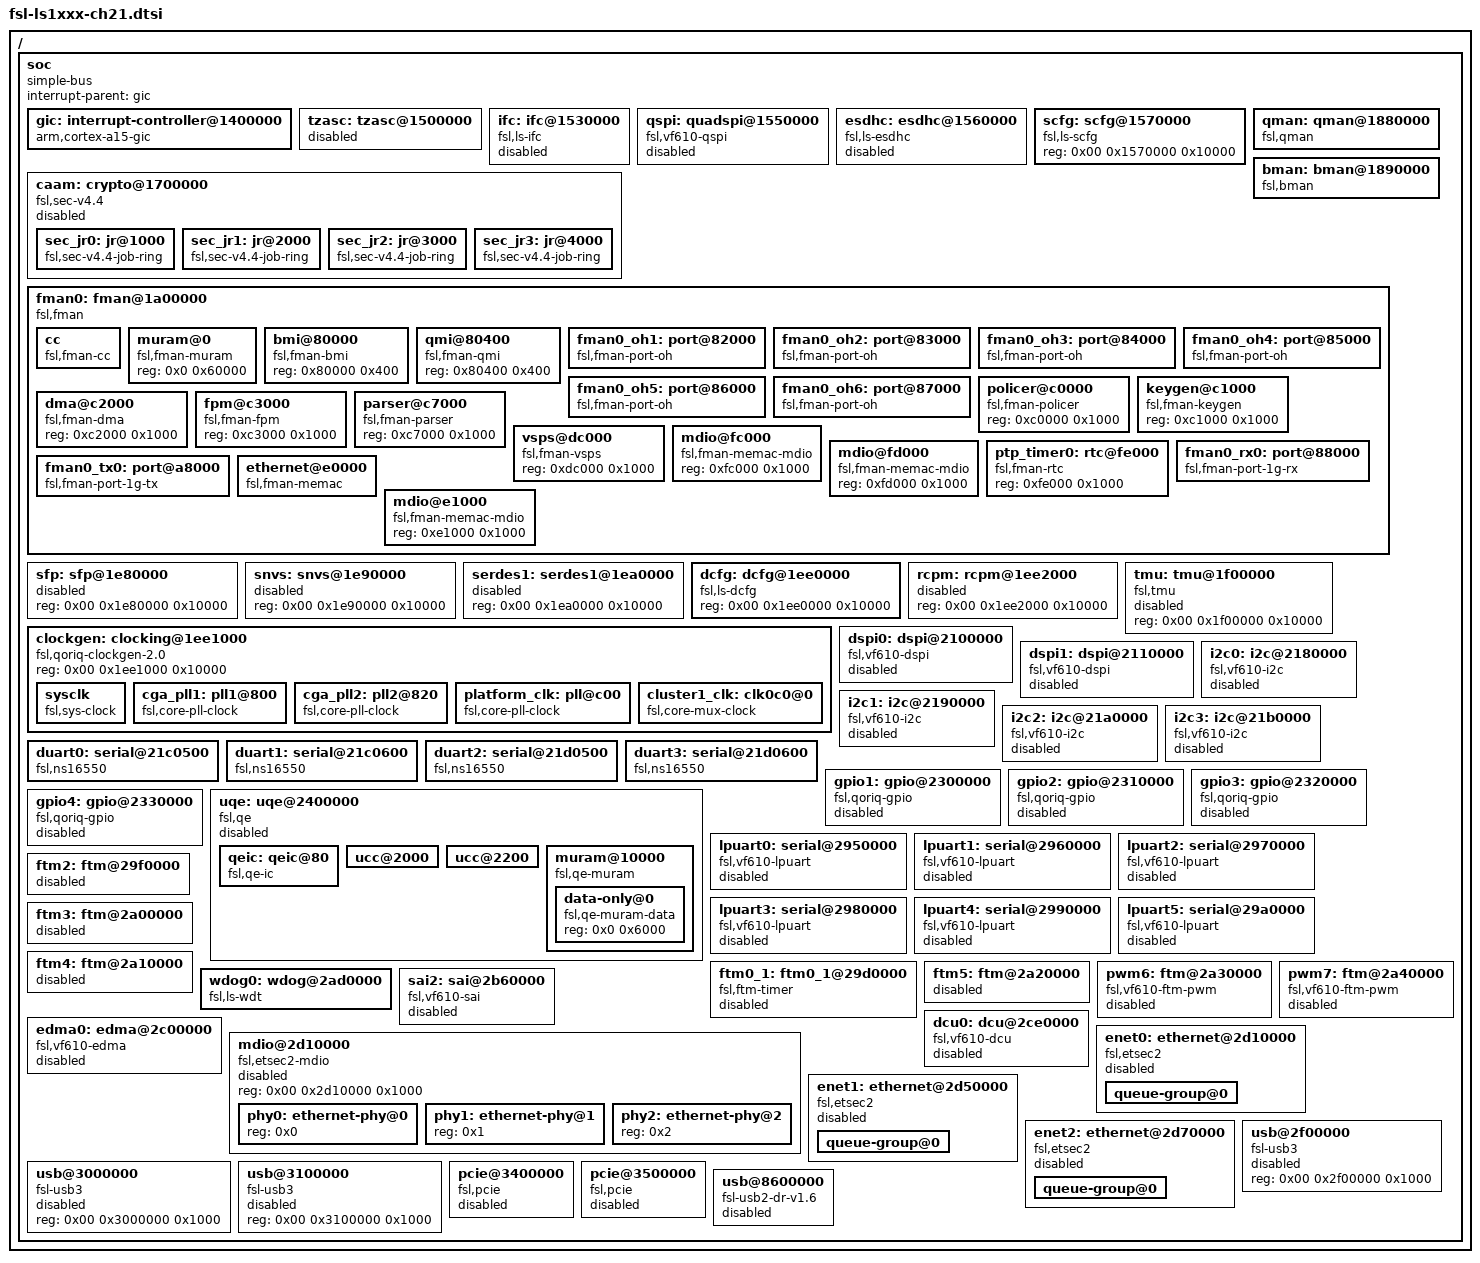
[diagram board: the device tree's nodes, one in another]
/*
 * Device Tree Include file for Freescale Layerscape 1xxx family SoC
 * (compliant to Chassis 2.1 specifications).
 *
 * Copyright 2014, Freescale Semiconductor Inc.
 * Li Yang <leoli@freescale.com>
 *
 * Redistribution and use in source and binary forms, with or without
 * modification, are permitted provided that the following conditions are met:
 *     * Redistributions of source code must retain the above copyright
 *       notice, this list of conditions and the following disclaimer.
 *     * Redistributions in binary form must reproduce the above copyright
 *       notice, this list of conditions and the following disclaimer in the
 *       documentation and/or other materials provided with the distribution.
 *     * Neither the name of Freescale Semiconductor nor the
 *       names of its contributors may be used to endorse or promote products
 *       derived from this software without specific prior written permission.
 *
 *
 * ALTERNATIVELY, this software may be distributed under the terms of the
 * GNU General Public License ("GPL") as published by the Free Software
 * Foundation, either version 2 of that License or (at your option) any
 * later version.
 *
 * THIS SOFTWARE IS PROVIDED BY Freescale Semiconductor ``AS IS'' AND ANY
 * EXPRESS OR IMPLIED WARRANTIES, INCLUDING, BUT NOT LIMITED TO, THE IMPLIED
 * WARRANTIES OF MERCHANTABILITY AND FITNESS FOR A PARTICULAR PURPOSE ARE
 * DISCLAIMED. IN NO EVENT SHALL Freescale Semiconductor BE LIABLE FOR ANY
 * DIRECT, INDIRECT, INCIDENTAL, SPECIAL, EXEMPLARY, OR CONSEQUENTIAL DAMAGES
 * (INCLUDING, BUT NOT LIMITED TO, PROCUREMENT OF SUBSTITUTE GOODS OR SERVICES;
 * LOSS OF USE, DATA, OR PROFITS; OR BUSINESS INTERRUPTION) HOWEVER CAUSED AND
 * ON ANY THEORY OF LIABILITY, WHETHER IN CONTRACT, STRICT LIABILITY, OR TORT
 * (INCLUDING NEGLIGENCE OR OTHERWISE) ARISING IN ANY WAY OUT OF THE USE OF THIS
 * SOFTWARE, EVEN IF ADVISED OF THE POSSIBILITY OF SUCH DAMAGE.
 */

/ {

	soc {
		#address-cells = <2>;
		#size-cells = <1>;
		compatible = "simple-bus";
		interrupt-parent = <&gic>;

		gic: interrupt-controller@1400000 {
			compatible = "arm,cortex-a15-gic";
			#interrupt-cells = <3>;
			interrupt-controller;
			reg = <0x00 0x1401000 0x1000>,
				<0x00 0x1402000 0x1000>,
				<0x00 0x1404000 0x2000>,
				<0x00 0x1406000 0x2000>;
		};

		tzasc: tzasc@1500000 {
			reg = <0x00 0x1500000 0x10000>;
			interrupts = <0 93 0x04>;
			status = "disabled";
		};

		ifc: ifc@1530000 {
			compatible = "fsl,ls-ifc", "fsl,ifc", "simple-bus";
			reg = <0x00 0x1530000 0x10000>;
			interrupts = <0 43 0x04>;
			status = "disabled";
		};

		qspi: quadspi@1550000 {
			#address-cells = <1>;
			#size-cells = <0>;
			compatible = "fsl,vf610-qspi";
			reg = <0x00 0x1550000 0x10000>;
			interrupts = <0 99 0x04>;
			clock-names = "qspi_en", "qspi";
			status = "disabled";
		};

		esdhc: esdhc@1560000 {
			compatible = "fsl,ls-esdhc", "fsl,esdhc";
			reg = <0x00 0x1560000 0x10000>;
			interrupts = <0 62 0x04>;
			clock-frequency = <0>;
			voltage-ranges = <1800 3300>;
			bus-width = <4>;
			status = "disabled";
		};

		scfg: scfg@1570000 {
			compatible = "fsl,ls-scfg";
			reg = <0x00 0x1570000 0x10000>;
		};

		caam: crypto@1700000 {
			compatible = "fsl,sec-v4.4", "fsl,sec-v4.0";
			fsl,sec-era = <3>;
			#address-cells = <1>;
			#size-cells = <1>;
			ranges = <0x0 0x00 0x1700000 0x10000>;
			reg = <0x00 0x1700000 0x10000>;
			interrupts	 = <0 75 0x04>;
			status = "disabled";

			sec_jr0: jr@1000 {
				compatible = "fsl,sec-v4.4-job-ring", "fsl,sec-v4.0-job-ring";
				reg	   = <0x1000 0x1000>;
				interrupts = <0 71 0x04>;
			};

			sec_jr1: jr@2000 {
				compatible = "fsl,sec-v4.4-job-ring", "fsl,sec-v4.0-job-ring";
				reg	   = <0x2000 0x1000>;
				interrupts = <0 72 0x04>;
			};

			sec_jr2: jr@3000 {
				compatible = "fsl,sec-v4.4-job-ring", "fsl,sec-v4.0-job-ring";
				reg	   = <0x3000 0x1000>;
				interrupts = <0 73 0x04>;
			};

			sec_jr3: jr@4000 {
				compatible = "fsl,sec-v4.4-job-ring", "fsl,sec-v4.0-job-ring";
				reg	   = <0x4000 0x1000>;
				interrupts = <0 74 0x04>;
			};
		};

		qman: qman@1880000 {
			compatible = "fsl,qman";
			reg = <0x00 0x1880000 0x10000>;
			interrupts = <0 77 0x4>;
		};

		bman: bman@1890000 {
			compatible = "fsl,bman";
			reg = <0x00 0x1890000 0x10000>;
			interrupts = <0 77 0x4>;
		};

		fman0: fman@1a00000 {
			#address-cells = <1>;
			#size-cells = <1>;
			cell-index = <0>;
			compatible = "fsl,fman", "simple-bus";
			ranges = <0x0 0x00 0x1a00000 0x100000>;
			reg = <0x00 0x1a00000 0x100000>;
			clock-frequency = <0>;
			interrupts =	<0 44 0x04>,	/* fman 76 (-32)*/
					<0 45 0x04>;	/* fman-error 77 (-32)*/

			cc {
				compatible = "fsl,fman-cc";
			};

			muram@0 {
				compatible = "fsl,fman-muram";
				reg = <0x0 0x60000>;
			};

			bmi@80000 {
				compatible = "fsl,fman-bmi";
				reg = <0x80000 0x400>;
			};

			qmi@80400 {
				compatible = "fsl,fman-qmi";
				reg = <0x80400 0x400>;
			};

			fman0_oh1: port@82000 {
				cell-index = <0>;
				compatible = "fsl,fman-port-oh";
				reg = <0x82000 0x1000>;
				fsl,qman-channel-id = <0x802>;
			};

			fman0_oh2: port@83000 {
				cell-index = <1>;
				compatible = "fsl,fman-port-oh";
				reg = <0x83000 0x1000>;
				fsl,qman-channel-id = <0x803>;
			};

			fman0_oh3: port@84000 {
				cell-index = <2>;
				compatible = "fsl,fman-port-oh";
				reg = <0x84000 0x1000>;
				fsl,qman-channel-id = <0x804>;
			};

			fman0_oh4: port@85000 {
				cell-index = <3>;
				compatible = "fsl,fman-port-oh";
				reg = <0x85000 0x1000>;
				fsl,qman-channel-id = <0x805>;
			};

			fman0_oh5: port@86000 {
				cell-index = <4>;
				compatible = "fsl,fman-port-oh";
				reg = <0x86000 0x1000>;
				fsl,qman-channel-id = <0x806>;
			};

			fman0_oh6: port@87000 {
				cell-index = <5>;
				compatible = "fsl,fman-port-oh";
				reg = <0x87000 0x1000>;
				fsl,qman-channel-id = <0x807>;
			};

			policer@c0000 {
				compatible = "fsl,fman-policer";
				reg = <0xc0000 0x1000>;
			};

			keygen@c1000 {
				compatible = "fsl,fman-keygen";
				reg = <0xc1000 0x1000>;
			};

			dma@c2000 {
				compatible = "fsl,fman-dma";
				reg = <0xc2000 0x1000>;
			};

			fpm@c3000 {
				compatible = "fsl,fman-fpm";
				reg = <0xc3000 0x1000>;
			};

			parser@c7000 {
				compatible = "fsl,fman-parser";
				reg = <0xc7000 0x1000>;
			};

			vsps@dc000 {
				compatible = "fsl,fman-vsps";
				reg = <0xdc000 0x1000>;
			};

			mdio@fc000 {
				#address-cells = <1>;
				#size-cells = <0>;
				compatible = "fsl,fman-memac-mdio";
				reg = <0xfc000 0x1000>;
			};

			mdio@fd000 {
				#address-cells = <1>;
				#size-cells = <0>;
				compatible = "fsl,fman-memac-mdio";
				reg = <0xfd000 0x1000>;
			};

			ptp_timer0: rtc@fe000 {
				compatible = "fsl,fman-rtc";
				reg = <0xfe000 0x1000>;
			};

			fman0_rx0: port@88000 {
				cell-index = <0>;
				compatible = "fsl,fman-port-1g-rx";
				reg = <0x88000 0x1000>;
			};

			fman0_tx0: port@a8000 {
				cell-index = <0>;
				compatible = "fsl,fman-port-1g-tx";
				reg = <0xa8000 0x1000>;
				fsl,qman-channel-id = <0x802>;
			};

			ethernet@e0000 {
				cell-index = <0>;
				compatible = "fsl,fman-memac";
				reg = <0xe0000 0x1000>;
				fsl,port-handles = <&fman0_rx0 &fman0_tx0>;
				ptimer-handle = <&ptp_timer0>;
			};

			mdio@e1000 {
				#address-cells = <1>;
				#size-cells = <0>;
				compatible = "fsl,fman-memac-mdio";
				reg = <0xe1000 0x1000>;
			};
		};

		sfp: sfp@1e80000 {
			reg = <0x00 0x1e80000 0x10000>;
			status = "disabled";
		};

		snvs: snvs@1e90000 {
			reg = <0x00 0x1e90000 0x10000>;
			status = "disabled";
		};

		serdes1: serdes1@1ea0000 {
			reg = <0x00 0x1ea0000 0x10000>;
			status = "disabled";
		};

		dcfg: dcfg@1ee0000 {
			compatible = "fsl,ls-dcfg";
			reg = <0x00 0x1ee0000 0x10000>;
		};

		clockgen: clocking@1ee1000 {
			compatible = "fsl,qoriq-clockgen-2.0";
			reg = <0x00 0x1ee1000 0x10000>;
			#address-cells = <1>;
			#size-cells = <0>;
			sysclk: sysclk {
				compatible = "fsl,sys-clock";
				#clock-cells = <0>;
				clock-frequency = <100000000>;
				clock-output-names = "sysclk";
			};

			cga_pll1: pll1@800 {
				compatible = "fsl,core-pll-clock";
				#clock-cells = <1>;
				reg = <0x800>;
				clocks = <&sysclk>;
				clock-output-names = "cga-pll1", "cga-pll1-div2",
						"cga-pll1-div3", "cga-pll1-div4";
			};

			cga_pll2: pll2@820 {
				compatible = "fsl,core-pll-clock";
				#clock-cells = <1>;
				reg = <0x820>;
				clocks = <&sysclk>;
				clock-output-names = "cga-pll2", "cga-pll2-div2",
						"cga-pll2-div3", "cga-pll2-div4";
			};

			platform_clk: pll@c00 {
				compatible = "fsl,core-pll-clock";
				#clock-cells = <1>;
				reg = <0xc00>;
				clocks = <&sysclk>;
				clock-output-names = "platform-clk", "platform-clk-div2";
			};


			cluster1_clk: clk0c0@0 {
				compatible = "fsl,core-mux-clock";
				#clock-cells = <1>;
				reg = <0x0>;
				clock-names = "pll1cga", "pll1cga-div2";
				clocks = <&cga_pll1 0>, <&cga_pll1 2>;
				clock-output-names = "cluster1-clk";

			};

		};

		rcpm: rcpm@1ee2000 {
			reg = <0x00 0x1ee2000 0x10000>;
			status = "disabled";
		};

		tmu: tmu@1f00000 {
			compatible = "fsl,tmu";
			reg = <0x00 0x1f00000 0x10000>;
			status = "disabled";
		};

		dspi0: dspi@2100000 {
			#address-cells = <1>;
			#size-cells = <0>;
			compatible = "fsl,vf610-dspi";
			reg = <0x00 0x2100000 0x10000>;
			interrupts = <0 64 0x04>;
			clock-names = "dspi";
			clocks = <&platform_clk 1>;
			spi-num-chipselects = <5>;
			big-endian;
			status = "disabled";
		};

		dspi1: dspi@2110000 {
			#address-cells = <1>;
			#size-cells = <0>;
			compatible = "fsl,vf610-dspi";
			reg = <0x00 0x2110000 0x10000>;
			interrupts = <0 65 0x04>;
			clock-names = "dspi";
			clocks = <&platform_clk 1>;
			spi-num-chipselects = <5>;
			big-endian;
			status = "disabled";
		};

		i2c0: i2c@2180000 {
			#address-cells = <1>;
			#size-cells = <0>;
			compatible = "fsl,vf610-i2c";
			reg = <0x00 0x2180000 0x10000>;
			interrupts =<0 56 0x04>;
			clock-names = "i2c";
			clocks = <&platform_clk 1>;
			dmas = <&edma0 1 39>,
				<&edma0 1 38>;
			dma-names = "tx", "rx";
			status = "disabled";
		};

		i2c1: i2c@2190000 {
			#address-cells = <1>;
			#size-cells = <0>;
			compatible = "fsl,vf610-i2c";
			reg = <0x00 0x2190000 0x10000>;
			interrupts = <0 57 0x04>;
			clock-names = "i2c";
			clocks = <&platform_clk 1>;
			status = "disabled";
		};

		i2c2: i2c@21a0000 {
			#address-cells = <1>;
			#size-cells = <0>;
			compatible = "fsl,vf610-i2c";
			reg = <0x00 0x21a0000 0x10000>;
			interrupts = <0 58 0x04>;
			clock-names = "i2c";
			clocks = <&platform_clk 1>;
			status = "disabled";
		};

		i2c3: i2c@21b0000 {
			#address-cells = <1>;
			#size-cells = <0>;
			compatible = "fsl,vf610-i2c";
			reg = <0x00 0x21b0000 0x10000>;
			interrupts = <0 59 0x04>;
			clock-names = "i2c";
			clocks = <&platform_clk 1>;
			status = "disabled";
		};

		duart0: serial@21c0500 {
			compatible = "fsl,ns16550", "ns16550a";
			reg = <0x00 0x21c0500 0x100>;
			interrupts = <0 54 0x04>;
			clock-frequency = <66666666>;
			fifo-size = <64>;
		};

		duart1: serial@21c0600 {
			compatible = "fsl,ns16550", "ns16550a";
			reg = <0x00 0x21c0600 0x100>;
			interrupts = <0 54 0x04>;
			clock-frequency = <66666666>;
			fifo-size = <64>;
		};

		duart2: serial@21d0500 {
			compatible = "fsl,ns16550", "ns16550a";
			reg = <0x00 0x21d0500 0x100>;
			interrupts = <0 55 0x04>;
			clock-frequency = <66666666>;
			fifo-size = <64>;
		};

		duart3: serial@21d0600 {
			compatible = "fsl,ns16550", "ns16550a";
			reg = <0x00 0x21d0600 0x100>;
			interrupts = <0 55 0x04>;
			clock-frequency = <66666666>;
			fifo-size = <64>;
		};

		gpio1: gpio@2300000 {
			compatible = "fsl,qoriq-gpio";
			reg = <0x00 0x2300000 0x10000>;
			interrupts = <0 66 0x04>;
			gpio-controller;
			#gpio-cells = <2>;
			interrupt-controller;
			#interrupt-cells = <2>;
			status = "disabled";
		};

		gpio2: gpio@2310000 {
			compatible = "fsl,qoriq-gpio";
			reg = <0x00 0x2310000 0x10000>;
			interrupts = <0 67 0x04>;
			gpio-controller;
			#gpio-cells = <2>;
			interrupt-controller;
			#interrupt-cells = <2>;
			status = "disabled";
		};

		gpio3: gpio@2320000 {
			compatible = "fsl,qoriq-gpio";
			reg = <0x00 0x2320000 0x10000>;
			interrupts = <0 68 0x04>;
			gpio-controller;
			#gpio-cells = <2>;
			interrupt-controller;
			#interrupt-cells = <2>;
			status = "disabled";
		};

		gpio4: gpio@2330000 {
			compatible = "fsl,qoriq-gpio";
			reg = <0x00 0x2330000 0x10000>;
			interrupts = <0 134 0x04>;
			gpio-controller;
			#gpio-cells = <2>;
			interrupt-controller;
			#interrupt-cells = <2>;
			status = "disabled";
		};

		uqe: uqe@2400000 {
			#address-cells = <1>;
			#size-cells = <1>;
			ranges = <0x0 0x00 0x2400000 0x40000>;
			device_type = "qe";
			compatible = "fsl,qe";
			fsl,qe-num-riscs = <1>;
			fsl,qe-num-snums = <28>;
			status = "disabled";

			qeic: qeic@80 {
				compatible = "fsl,qe-ic";
				reg = <0x80 0x80>;
				#address-cells = <0>;
				interrupt-controller;
				#interrupt-cells = <1>;
				interrupts = <0 77 0x04>;
			};

			ucc@2000 {
				cell-index = <1>;
				reg = <0x2000 0x200>;
				interrupts = <32>;
				interrupt-parent = <&qeic>;
			};

			ucc@2200 {
				cell-index = <3>;
				reg = <0x2200 0x200>;
				interrupts = <34>;
				interrupt-parent = <&qeic>;
			};

			muram@10000 {
				#address-cells = <1>;
				#size-cells = <1>;
				compatible = "fsl,qe-muram", "fsl,cpm-muram";
				ranges = <0x0 0x10000 0x6000>;

				data-only@0 {
					compatible = "fsl,qe-muram-data",
					"fsl,cpm-muram-data";
					reg = <0x0 0x6000>;
				};
			};
		};

		lpuart0: serial@2950000 {
			compatible = "fsl,vf610-lpuart";
			reg = <0x00 0x2950000 0x1000>;
			interrupts = <0 48 0x04>;
			clocks = <&platform_clk 1>;
			clock-names = "ipg";
			status = "disabled";
		};

		lpuart1: serial@2960000 {
			compatible = "fsl,vf610-lpuart";
			reg = <0x00 0x2960000 0x1000>;
			interrupts = <0 49 0x04>;
			clocks = <&platform_clk 1>;
			clock-names = "ipg";
			status = "disabled";
		};

		lpuart2: serial@2970000 {
			compatible = "fsl,vf610-lpuart";
			reg = <0x00 0x2970000 0x1000>;
			interrupts = <0 50 0x04>;
			clocks = <&platform_clk 1>;
			clock-names = "ipg";
			status = "disabled";
		};

		lpuart3: serial@2980000 {
			compatible = "fsl,vf610-lpuart";
			reg = <0x00 0x2980000 0x1000>;
			interrupts = <0 51 0x04>;
			clocks = <&platform_clk 1>;
			clock-names = "ipg";
			status = "disabled";
		};

		lpuart4: serial@2990000 {
			compatible = "fsl,vf610-lpuart";
			reg = <0x00 0x2990000 0x1000>;
			interrupts = <0 52 0x04>;
			clocks = <&platform_clk 1>;
			clock-names = "ipg";
			status = "disabled";
		};

		lpuart5: serial@29a0000 {
			compatible = "fsl,vf610-lpuart";
			reg = <0x00 0x29a0000 0x1000>;
			interrupts = <0 53 0x04>;
			clocks = <&platform_clk 1>;
			clock-names = "ipg";
			status = "disabled";
		};

		ftm0_1: ftm0_1@29d0000 {
			compatible = "fsl,ftm-timer";
			reg = <0x00 0x29d0000 0x10000 0x00 0x29e0000 0x10000>;
			interrupts = <0 86 0x04>;
			clock-names = "ftm-evt", "ftm-src",
			        "ftm-evt-counter-en", "ftm-src-counter-en";
			clocks = <&platform_clk 1>, <&platform_clk 1>,
			       <&platform_clk 1>, <&platform_clk 1>;
			big-endian;
			status = "disabled";
		};

		ftm2: ftm@29f0000 {
			reg = <0x00 0x29f0000 0x10000>;
			interrupts = <0 88 0x04>;
			status = "disabled";
		};

		ftm3: ftm@2a00000 {
			reg = <0x00 0x2a00000 0x10000>;
			interrupts = <0 89 0x04>;
			status = "disabled";
		};

		ftm4: ftm@2a10000 {
			reg = <0x00 0x2a10000 0x10000>;
			interrupts = <0 0 0x04>;
			status = "disabled";
		};

		ftm5: ftm@2a20000 {
			reg = <0x00 0x2a20000 0x10000>;
			interrupts = <0 1 0x04>;
			status = "disabled";
		};

		pwm6: ftm@2a30000 {
			compatible = "fsl,vf610-ftm-pwm";
			#pwm-cells = <3>;
			reg = <0x00 0x2a30000 0x10000>;
			interrupts = <0 91 0x04>;
			clock-names = "ftm_sys", "ftm_ext",
				"ftm_fix", "ftm_cnt_clk_en";
			clocks = <&platform_clk 1>, <&platform_clk 1>,
				<&platform_clk 1>, <&platform_clk 1>;
			big-endian;
			status = "disabled";
		};

		pwm7: ftm@2a40000 {
			compatible = "fsl,vf610-ftm-pwm";
			#pwm-cells = <3>;
			reg = <0x00 0x2a40000 0x10000>;
			interrupts = <0 92 0x04>;
			clock-names = "ftm_sys", "ftm_ext",
				"ftm_fix", "ftm_cnt_clk_en";
			clocks = <&platform_clk 1>, <&platform_clk 1>,
				<&platform_clk 1>, <&platform_clk 1>;
			big-endian;
			status = "disabled";
		};

		wdog0: wdog@2ad0000 {
			compatible = "fsl,ls-wdt", "fsl,imx21-wdt";
			reg = <0x00 0x2ad0000 0x10000>;
			interrupts = <0 83 0x04>;
			clocks = <&platform_clk 1>;
			clock-names = "wdog";
		};

		sai2: sai@2b60000 {
			compatible = "fsl,vf610-sai";
			reg = <0x00 0x2b60000 0x10000>;
			interrupts = <0 101 0x04>;
			clocks = <&platform_clk 1>;
			clock-names = "sai";
			dma-names = "tx", "rx";
			dmas = <&edma0 1 45>,
				<&edma0 1 44>;
			big-endian-regs;
			status = "disabled";
		};

		edma0: edma@2c00000 {
			#dma-cells = <2>;
			compatible = "fsl,vf610-edma";
			reg = <0x00 0x2c00000 0x10000>,
				<0x00 0x2c10000 0x10000>,
				<0x00 0x2c20000 0x10000>;
			interrupts = <0 103 0x04>,
					<0 103 0x04>;
			interrupt-names = "edma-tx", "edma-err";
			dma-channels = <32>;
			big-endian;
			clock-names = "dmamux0", "dmamux1";
			clocks = <&platform_clk 1>,
				<&platform_clk 1>;
			status = "disabled";
		};

		dcu0: dcu@2ce0000 {
			compatible = "fsl,vf610-dcu";
			reg = <0x00 0x2ce000 0x10000>;
			interrupts = <0 140 0x04>;
			clocks = <&platform_clk 1>;
			clock-names = "dcu";
			big-endian;
			status = "disabled";
		};

		mdio@2d10000 {
			#address-cells = <1>;
			#size-cells = <0>;
			compatible = "fsl,etsec2-mdio";
			reg = <0x00 0x2d10000 0x1000>;
			status = "disabled";

			phy0: ethernet-phy@0 {
				reg = <0x0>;
			};
			phy1: ethernet-phy@1 {
				reg = <0x1>;
			};
			phy2: ethernet-phy@2 {
				reg = <0x2>;
			};
		};

		enet0: ethernet@2d10000 {
			#address-cells = <1>;
			#size-cells = <1>;
			device_type = "network";
			model = "eTSEC";
			compatible = "fsl,etsec2";
			fsl,num_rx_queues = <0x8>;
			fsl,num_tx_queues = <0x8>;
			local-mac-address = [ 00 00 00 00 00 00 ];
			status = "disabled";

			queue-group@0 {
				#address-cells = <1>;
				#size-cells = <1>;
				reg = <0x2d10000 0x1000>;
				fsl,rx-bit-map = <0xff>;
				fsl,tx-bit-map = <0xff>;
				interrupts = <0 112 0x04>,
					<0 113 0x04>,
					<0 114 0x04>;
			};

		};

		enet1: ethernet@2d50000 {
			#address-cells = <1>;
			#size-cells = <1>;
			device_type = "network";
			model = "eTSEC";
			compatible = "fsl,etsec2";
			fsl,num_rx_queues = <0x8>;
			fsl,num_tx_queues = <0x8>;
			local-mac-address = [ 00 00 00 00 00 00 ];
			status = "disabled";

			queue-group@0 {
				#address-cells = <1>;
				#size-cells = <1>;
				reg = <0x2d50000 0x1000>;
				fsl,rx-bit-map = <0xff>;
				fsl,tx-bit-map = <0xff>;
				interrupts = <0 118 0x04>,
					<0 120 0x04>,
					<0 121 0x04>;
			};

		};

		enet2: ethernet@2d70000 {
			#address-cells = <1>;
			#size-cells = <1>;
			device_type = "network";
			model = "eTSEC";
			compatible = "fsl,etsec2";
			fsl,num_rx_queues = <0x8>;
			fsl,num_tx_queues = <0x8>;
			local-mac-address = [ 00 00 00 00 00 00 ];
			status = "disabled";

			queue-group@0 {
				#address-cells = <1>;
				#size-cells = <1>;
				reg = <0x2d70000 0x1000>;
				fsl,rx-bit-map = <0xff>;
				fsl,tx-bit-map = <0xff>;
				interrupts = <0 125 0x04>,
					<0 126 0x04>,
					<0 127 0x04>;
			};
		};

		usb@2f00000 {
			compatible = "fsl-usb3"; /* FIXME */
			reg = <0x00 0x2f00000 0x1000>;
			status = "disabled";
		};

		usb@3000000 {
			compatible = "fsl-usb3"; /* FIXME */
			reg = <0x00 0x3000000 0x1000>;
			status = "disabled";
		};

		usb@3100000 {
			compatible = "fsl-usb3"; /* FIXME */
			reg = <0x00 0x3100000 0x1000>;
			status = "disabled";
		};

		pcie@3400000 {
			compatible = "fsl,pcie", "snps,dw-pcie", "fsl,ls-pcie";
			reg = <0x00 0x3400000 0x10000>;
			interrupts = <0 145 0x04>, <0 147 0x04>, <0 149 0x04>, <0 151 0x04>, <0 59 0x04>;
			interrupt-names = "intr", "msi", "pme", "cfg-err", "inta";
			#address-cells = <3>;
			#size-cells = <2>;
			device_type = "pci";
			num-lanes = <4>;
			bus-range = <0x0 0xff>;
			ranges = <0x00000800 0x0 0x00000000 0x40 0x00000000 0x0 0x00080000 /* configuration space */
				  0x81000000 0x0 0x00000000 0x40 0x10000000 0x0 0x00010000 /* downstream I/O */
				  0x82000000 0x0 0x00000000 0x41 0x00000000 0x1 0x00000000>; /* non-prefetchable memory */
			interrupt-map-mask = <0 0 0 7>;
			interrupt-map = <0000 0 0 1 &gic 0 59  0x04>,
					<0000 0 0 2 &gic 0 156 0x04>,
					<0000 0 0 3 &gic 0 158 0x04>,
					<0000 0 0 4 &gic 0 160 0x04>;
			status = "disabled";
			};

		pcie@3500000 {
			compatible = "fsl,pcie", "snps,dw-pcie", "fsl,ls-pcie";
			reg = <0x00 0x3500000 0x10000>;
			interrupts = <0 146 0>, <0 148 0>, <0 150 0>, <0 152 0>;
			interrupt-names = "intr", "msi", "pme", "cfg-err";
			#address-cells = <3>;
			#size-cells = <2>;
			device_type = "pci";
			num-lanes = <2>;
			bus-range = <0x0 0xff>;
			ranges = <0x82000000 0x0 0x00000000 0x48 0x00000000 0x0 0x10000000 /* configuration space */
				  0x81000000 0x0 0x00000000 0x48 0x10000000 0x0 0x00010000 /* downstream I/O */
				  0x82000000 0x0 0x00000000 0x49 0x00000000 0x1 0x00000000>; /* non-prefetchable memory */
			interrupt-map-mask = <0 0 0 7>;
			interrupt-map = <0000 0 0 1 &gic 0 59  0>,
					<0000 0 0 2 &gic 0 157 0>,
					<0000 0 0 3 &gic 0 159 0>,
					<0000 0 0 4 &gic 0 161 0>;
			status = "disabled";
		};

		usb@8600000 {
			compatible = "fsl-usb2-dr-v1.6", "fsl-usb2-dr";
			reg = <0x00 0x8600000 0x1000>;
			#address-cells = <1>;
			#size-cells = <0>;
			interrupts = <0 139 0x04>;
			dr_mode = "host";
			phy_type = "utmi";
			status = "disabled";
		};
	};
};
